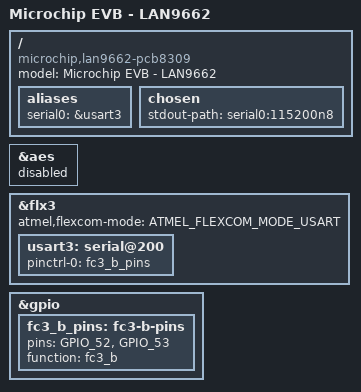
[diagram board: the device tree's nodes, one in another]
// SPDX-License-Identifier: (GPL-2.0+ OR MIT)
/*
 * lan966x_pcb8309.dts - Device Tree file for PCB8309
 */
/dts-v1/;
#include "lan966x.dtsi"

/ {
	model = "Microchip EVB - LAN9662";
	compatible = "microchip,lan9662-pcb8309", "microchip,lan9662", "microchip,lan966";

	aliases {
		serial0 = &usart3;
	};

	chosen {
		stdout-path = "serial0:115200n8";
	};
};

&aes {
	status = "disabled"; /* Reserved by secure OS */
};

&flx3 {
	atmel,flexcom-mode = <ATMEL_FLEXCOM_MODE_USART>;
	status = "okay";

	usart3: serial@200 {
		pinctrl-0 = <&fc3_b_pins>;
		pinctrl-names = "default";
		status = "okay";
	};
};

&gpio {
	fc3_b_pins: fc3-b-pins {
		/* RXD, TXD */
		pins = "GPIO_52", "GPIO_53";
		function = "fc3_b";
	};
};
